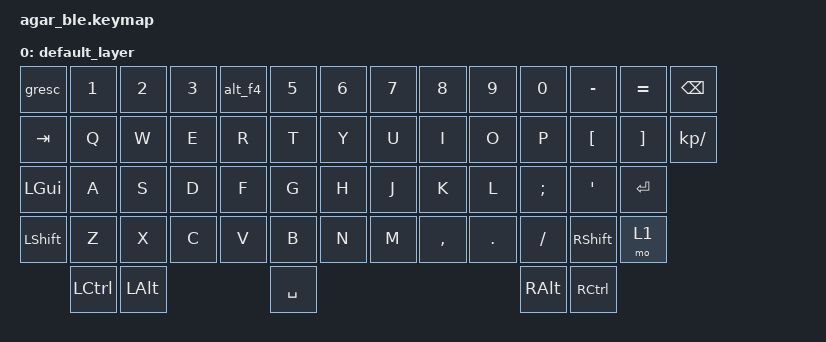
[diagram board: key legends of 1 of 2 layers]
#include <behaviors.dtsi>
#include <dt-bindings/zmk/bt.h>
#include <dt-bindings/zmk/keys.h>
#include <dt-bindings/zmk/outputs.h>
#include "common.keymap"

/ {
    behaviors {
        alt_f4: alt_f4 {
            compatible = "zmk,behavior-mod-morph";
            label = "ALT_F4";
            bindings = <&kp NUMBER_4>, <&kp LA(F4)>;

            #binding-cells = <0>;
            mods = <(MOD_LALT)>;
        };

        bt00: bt00 {
            compatible = "zmk,behavior-hold-tap";
            label = "BT00";
            bindings = <&bt0_clr>, <&bt_sel_0>;

            #binding-cells = <2>;
            flavor = "tap-preferred";
            tapping-term-ms = <1000>;
        };

        bt01: bt01 {
            compatible = "zmk,behavior-hold-tap";
            label = "BT01";
            bindings = <&bt1_clr>, <&bt_sel_1>;

            #binding-cells = <2>;
            flavor = "tap-preferred";
            tapping-term-ms = <1000>;
        };

        bt03: bt03 {
            compatible = "zmk,behavior-hold-tap";
            label = "BT03";
            bindings = <&bt3_clr>, <&bt_sel_3>;

            #binding-cells = <2>;
            flavor = "tap-preferred";
            tapping-term-ms = <1000>;
        };
    };

    macros {
        bt_sel_0: bt_sel_0 {
            compatible = "zmk,behavior-macro";
            #binding-cells = <0>;
            bindings = <&out OUT_BLE &bt BT_SEL 0>;
            label = "BT_SEL_0";
        };

        bt_sel_1: bt_sel_1 {
            compatible = "zmk,behavior-macro";
            #binding-cells = <0>;
            bindings = <&out OUT_BLE &bt BT_SEL 1>;
            label = "BT_SEL_1";
        };

        bt_sel_3: new_macro {
            compatible = "zmk,behavior-macro";
            #binding-cells = <0>;
            bindings = <&out OUT_BLE &bt BT_SEL 2>;
            label = "NEW_MACRO";
        };

        bt0_clr: bt0_clr {
            compatible = "zmk,behavior-macro";
            #binding-cells = <0>;
            bindings = <&out OUT_BLE &bt BT_SEL 0 &bt BT_CLR>;
            label = "BT0_CLR";
        };

        bt1_clr: bt1_clr {
            compatible = "zmk,behavior-macro";
            #binding-cells = <0>;
            bindings = <&out OUT_BLE &bt BT_SEL 1 &bt BT_CLR>;
            label = "BT1_CLR";
        };

        bt3_clr: bt2_clr {
            compatible = "zmk,behavior-macro";
            #binding-cells = <0>;
            bindings = <&out OUT_BLE &bt BT_SEL 2 &bt BT_CLR>;
            label = "BT2_CLR";
        };
    };

    keymap {
        compatible = "zmk,keymap";

        default_layer {
            bindings = <
&gresc     &kp N1     &kp N2    &kp N3  &alt_f4  &kp N5     &kp N6  &kp N7  &kp N8     &kp N9   &kp N0    &kp MINUS   &kp EQUAL  &kp BACKSPACE
&kp TAB    &kp Q      &kp W     &kp E   &kp R    &kp T      &kp Y   &kp U   &kp I      &kp O    &kp P     &kp LBKT    &kp RBKT   &kp KP_SLASH
&kp LGUI   &kp A      &kp S     &kp D   &kp F    &kp G      &kp H   &kp J   &kp K      &kp L    &kp SEMI  &kp SQT     &kp RET
&kp LSHFT  &kp Z      &kp X     &kp C   &kp V    &kp B      &kp N   &kp M   &kp COMMA  &kp DOT  &kp FSLH  &kp RSHIFT  &mo 1
           &kp LCTRL  &kp LALT                   &kp SPACE                                      &kp RALT  &kp RCTRL
            >;
        };

        layer1 {
            bindings = <
&kp CAPSLOCK  &kp F1     &kp F2     &kp F3     &kp F4  &kp F5       &kp F6  &kp F7      &kp F8           &kp F9             &kp F10       &kp F11    &kp F12     &kp DELETE
&out OUT_USB  &bt00 0 0  &bt01 0 0  &bt03 0 0  &trans  &trans       &trans  &trans      &trans           &trans             &kp UP_ARROW  &kp HOME   &kp END     &trans
&trans        &trans     &trans     &trans     &trans  &trans       &trans  &trans      &trans           &kp LEFT_ARROW     &kp DOWN      &kp RIGHT  &sys_reset
&trans        &trans     &trans     &trans     &trans  &trans       &trans  &kp C_MUTE  &kp C_VOLUME_UP  &kp C_VOLUME_DOWN  &trans        &trans     &trans
              &trans     &trans                        &bootloader
            >;
        };

        layer2 { status = "reserved"; };

        layer3 { status = "reserved"; };

        layer4 { status = "reserved"; };

        layer5 { status = "reserved"; };

        layer6 { status = "reserved"; };

        layer7 { status = "reserved"; };
    };
};
